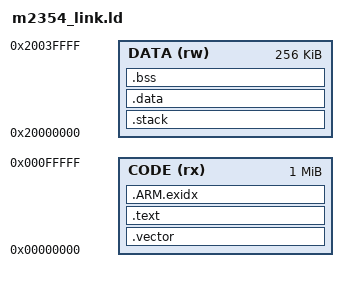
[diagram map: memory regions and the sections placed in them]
/*
 * @copyright (C) 2020 Nuvoton Technology Corp. All rights reserved.
 *
 * SPDX-License-Identifier: Apache-2.0
 *
 * Change Logs:
 * Date           Author       Notes
 * 2020-05-2      Wayne        First version
 */

/* Program Entry, set to mark it as "used" and avoid gc */
MEMORY
{
    CODE (rx) : ORIGIN = 0x00000000, LENGTH = 1024K   /* 1024K flash */
    DATA (rw) : ORIGIN = 0x20000000, LENGTH = 256K    /* 256K sram */
}
ENTRY(Reset_Handler)
_system_stack_size = 0x2000;

SECTIONS
{
    .vector :
    {
        . = ALIGN(4);
        _stext = .;
        KEEP(*(.isr_vector))            /* Startup code */
    } > CODE = 0
    
    .text :
    {
        . = ALIGN(4);
        *(.text)                        /* remaining code */
        *(.text.*)                      /* remaining code */
        *(.rodata)                      /* read-only data (constants) */
        *(.rodata*)
        *(.glue_7)
        *(.glue_7t)
        *(.gnu.linkonce.t*)

        /* section information for finsh shell */
        . = ALIGN(4);
        __fsymtab_start = .;
        KEEP(*(FSymTab))
        __fsymtab_end = .;
        . = ALIGN(4);
        __vsymtab_start = .;
        KEEP(*(VSymTab))
        __vsymtab_end = .;
        . = ALIGN(4);

        /* section information for initial. */
        . = ALIGN(4);
        __rt_init_start = .;
        KEEP(*(SORT(.rti_fn*)))
        __rt_init_end = .;
        . = ALIGN(4);

        /* section information for utest */
        . = ALIGN(4);
        __rt_utest_tc_tab_start = .;
        KEEP(*(UtestTcTab))
        __rt_utest_tc_tab_end = .;

        . = ALIGN(4);
        _etext = .;
    } > CODE = 0

    /* .ARM.exidx is sorted, so has to go in its own output section.  */
    __exidx_start = .;
    .ARM.exidx :
    {
        *(.ARM.exidx* .gnu.linkonce.armexidx.*)

        /* This is used by the startup in order to initialize the .data section */
        _sidata = .;
    } > CODE
    __exidx_end = .;

    .stack : 
    {
        _sstack = .;
        . = . + _system_stack_size;
        . = ALIGN(4);
        _estack = .;
    } >DATA

    /* .data section which is used for initialized data */
    .data : AT (_sidata)
    {
        . = ALIGN(4);
        /* This is used by the startup in order to initialize the .data section */
        _sdata = . ;

        *(.data)
        *(.data.*)
        *(.gnu.linkonce.d*)

        . = ALIGN(4);
        /* This is used by the startup in order to initialize the .data section */
        _edata = . ;
    } >DATA

    __bss_start = .;
    .bss :
    {
        . = ALIGN(4);
        /* This is used by the startup in order to initialize the .bss section */
        _sbss = .;

        *(.bss)
        *(.bss.*)
        *(COMMON)

        . = ALIGN(4);
        /* This is used by the startup in order to initialize the .bss section */
        _ebss = . ;
        
        *(.bss.init)
    } > DATA
    __bss_end = .;

    _end = .;
    
    __ram_top = ORIGIN(DATA) + LENGTH(DATA);

    /* Stabs debugging sections.  */
    .stab          0 : { *(.stab) }
    .stabstr       0 : { *(.stabstr) }
    .stab.excl     0 : { *(.stab.excl) }
    .stab.exclstr  0 : { *(.stab.exclstr) }
    .stab.index    0 : { *(.stab.index) }
    .stab.indexstr 0 : { *(.stab.indexstr) }
    .comment       0 : { *(.comment) }
    /* DWARF debug sections.
     * Symbols in the DWARF debugging sections are relative to the beginning
     * of the section so we begin them at 0.  */
    /* DWARF 1 */
    .debug          0 : { *(.debug) }
    .line           0 : { *(.line) }
    /* GNU DWARF 1 extensions */
    .debug_srcinfo  0 : { *(.debug_srcinfo) }
    .debug_sfnames  0 : { *(.debug_sfnames) }
    /* DWARF 1.1 and DWARF 2 */
    .debug_aranges  0 : { *(.debug_aranges) }
    .debug_pubnames 0 : { *(.debug_pubnames) }
    /* DWARF 2 */
    .debug_info     0 : { *(.debug_info .gnu.linkonce.wi.*) }
    .debug_abbrev   0 : { *(.debug_abbrev) }
    .debug_line     0 : { *(.debug_line) }
    .debug_frame    0 : { *(.debug_frame) }
    .debug_str      0 : { *(.debug_str) }
    .debug_loc      0 : { *(.debug_loc) }
    .debug_macinfo  0 : { *(.debug_macinfo) }
    /* SGI/MIPS DWARF 2 extensions */
    .debug_weaknames 0 : { *(.debug_weaknames) }
    .debug_funcnames 0 : { *(.debug_funcnames) }
    .debug_typenames 0 : { *(.debug_typenames) }
    .debug_varnames  0 : { *(.debug_varnames) }
}
